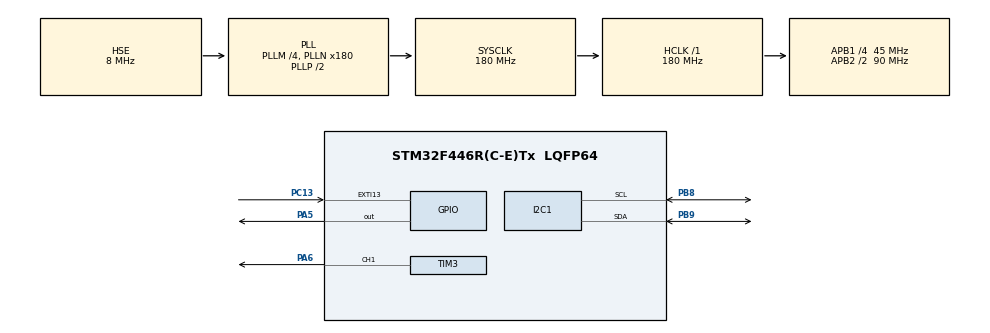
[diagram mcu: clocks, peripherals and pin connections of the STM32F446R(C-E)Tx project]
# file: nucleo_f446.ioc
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Mcu.Family=STM32F4
Mcu.Name=STM32F446R(C-E)Tx
Mcu.Package=LQFP64
NUCLEO-F446RE.BUTTON=1
NUCLEO-F446RE.LD1=true
NVIC.EXTI15_10_IRQn=true\:0\:0\:false\:false\:true\:false\:true\:true
NVIC.PriorityGroup=NVIC_PRIORITYGROUP_0
NVIC.TIM6_DAC_IRQn=true\:0\:0\:false\:false\:true\:false\:true\:true
NVIC.TimeBase=TIM6_DAC_IRQn
NVIC.TimeBaseIP=TIM6
PA13.GPIO_Label=TMS
PA13.Mode=Serial_Wire
PA13.Signal=SYS_JTMS-SWDIO
PA14.GPIO_Label=TCK
PA14.Mode=Serial_Wire
PA14.Signal=SYS_JTCK-SWCLK
PA2.GPIO_Label=USART_TX
PA2.Signal=USART2_TX
PA3.GPIO_Label=USART_RX
PA3.Signal=USART2_RX
PA5.Signal=GPIO_Output
PA6.Signal=S_TIM3_CH1
PB3.GPIO_Label=SWO
PB3.Signal=SYS_JTDO-SWO
PB8.Mode=I2C
PB8.Signal=I2C1_SCL
PB9.Mode=I2C
PB9.Signal=I2C1_SDA
PC13.Signal=GPXTI13
PC14-OSC32_IN.Signal=RCC_OSC32_IN
PC15-OSC32_OUT.Signal=RCC_OSC32_OUT
PH0-OSC_IN.Mode=HSE-External-Clock-Source
PH0-OSC_IN.Signal=RCC_OSC_IN
PH1-OSC_OUT.Mode=HSE-External-Clock-Source
PH1-OSC_OUT.Signal=RCC_OSC_OUT
ProjectManager.HeapSize=0x200
ProjectManager.StackSize=0x400
ProjectManager.TargetToolchain=CMake
RCC.AHBFreq_Value=180000000
RCC.APB1CLKDivider=RCC_HCLK_DIV4
RCC.APB1Freq_Value=45000000
RCC.APB1TimFreq_Value=90000000
RCC.APB2CLKDivider=RCC_HCLK_DIV2
RCC.APB2Freq_Value=90000000
RCC.APB2TimFreq_Value=180000000
RCC.CortexFreq_Value=180000000
RCC.FLatency-AdvancedSettings=FLASH_LATENCY_5
RCC.HCLKFreq_Value=180000000
RCC.HSE_VALUE=8000000
RCC.HSI_VALUE=16000000
RCC.LSE_VALUE=32768
RCC.PLLM=4
RCC.PLLN=180
RCC.PLLSourceVirtual=RCC_PLLSOURCE_HSE
RCC.SYSCLKFreq_VALUE=180000000
RCC.SYSCLKSource=RCC_SYSCLKSOURCE_PLLCLK
RCC.USBFreq_Value=180000000
RCC.VCOOutputFreq_Value=360000000
SH.S_TIM3_CH1.0=TIM3_CH1,PWM Generation1 CH1
TIM3.AutoReloadPreload=TIM_AUTORELOAD_PRELOAD_ENABLE
TIM3.Channel-PWM\ Generation1\ CH1=TIM_CHANNEL_1
TIM3.Period=19999
TIM3.Prescaler=89
TIM3.Pulse-PWM\ Generation1\ CH1=1500
VP_NUCLEO-F446RE_VS_BSP_COMMON.Mode=COMMON
VP_SYS_VS_tim6.Mode=TIM6
board=NUCLEO-F446RE

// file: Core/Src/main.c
/* USER CODE BEGIN Header */
/**
 ******************************************************************************
 * @file           : main.c
 * @brief          : Main program body
 ******************************************************************************
 * @attention
 *
 * Copyright (c) 2026 STMicroelectronics.
 * All rights reserved.
 *
 * This software is licensed under terms that can be found in the LICENSE file
 * in the root directory of this software component.
 * If no LICENSE file comes with this software, it is provided AS-IS.
 *
 ******************************************************************************
 */
/* USER CODE END Header */
#include "main.h"
#include "i2c.h"
#include "tim.h"
#include "gpio.h"

/* USER CODE BEGIN Includes */
#include "bno055_port.h"
#include "steering_port.h"

/* USER CODE END Includes */

void SystemClock_Config(void);

int main(void)
{

    /* MCU Configuration--------------------------------------------------------*/

    /* Reset of all peripherals, Initializes the Flash interface and the Systick. */
    HAL_Init();

    /* Configure the system clock */
    SystemClock_Config();

    /* Initialize all configured peripherals */
    MX_GPIO_Init();
    MX_I2C1_Init();
    MX_TIM3_Init();
    /* USER CODE BEGIN 2 */

    bno055_t bno055_dev = {0};
    bno055_port_init(&bno055_dev, &hi2c1);
    bno055_status_t imu_st = bno055_init(&bno055_dev, NULL);

    steering_dev_t steer_dev = {0};
    steering_cal_t steer_cal = {.left_us = 2000, .center_us = 1500, .right_us = 1000};
    steering_status_t steer_st = steering_port_init(&steer_dev, &htim3);

    if (steer_st == STEERING_OK) steer_st = steering_init(&steer_dev, &steer_cal);

    /* USER CODE END 2 */
    static uint16_t g_steer_us = 1500;

    /* Initialize leds */
    BSP_LED_Init(LED2);

    /* Initialize USER push-button, will be used to trigger an interrupt each time it's pressed.*/
    BSP_PB_Init(BUTTON_USER, BUTTON_MODE_EXTI);

    /* Infinite loop */
    while (1)
    {

        /* USER CODE BEGIN 3 */
        steering_set_pulse_us(&steer_dev, g_steer_us);
        bno055_vec3_t accel, gyro;
        bno055_read_accel(&bno055_dev, &accel);
        bno055_read_gyro(&bno055_dev, &gyro);
        HAL_Delay(100);
    }
    /* USER CODE END 3 */
}

void SystemClock_Config(void)
{
    RCC_OscInitTypeDef RCC_OscInitStruct = {0};
    RCC_ClkInitTypeDef RCC_ClkInitStruct = {0};

    /** Configure the main internal regulator output voltage
     */
    __HAL_RCC_PWR_CLK_ENABLE();
    __HAL_PWR_VOLTAGESCALING_CONFIG(PWR_REGULATOR_VOLTAGE_SCALE1);

    /** Initializes the RCC Oscillators according to the specified parameters
     * in the RCC_OscInitTypeDef structure.
     */
    RCC_OscInitStruct.OscillatorType = RCC_OSCILLATORTYPE_HSE;
    RCC_OscInitStruct.HSEState = RCC_HSE_BYPASS;
    RCC_OscInitStruct.PLL.PLLState = RCC_PLL_ON;
    RCC_OscInitStruct.PLL.PLLSource = RCC_PLLSOURCE_HSE;
    RCC_OscInitStruct.PLL.PLLM = 4;
    RCC_OscInitStruct.PLL.PLLN = 180;
    RCC_OscInitStruct.PLL.PLLP = RCC_PLLP_DIV2;
    RCC_OscInitStruct.PLL.PLLQ = 2;
    RCC_OscInitStruct.PLL.PLLR = 2;
    if (HAL_RCC_OscConfig(&RCC_OscInitStruct) != HAL_OK)
    {
        Error_Handler();
    }

    /** Activate the Over-Drive mode
     */
    if (HAL_PWREx_EnableOverDrive() != HAL_OK)
    {
        Error_Handler();
    }

    /** Initializes the CPU, AHB and APB buses clocks
     */
    RCC_ClkInitStruct.ClockType =
        RCC_CLOCKTYPE_HCLK | RCC_CLOCKTYPE_SYSCLK | RCC_CLOCKTYPE_PCLK1 | RCC_CLOCKTYPE_PCLK2;
    RCC_ClkInitStruct.SYSCLKSource = RCC_SYSCLKSOURCE_PLLCLK;
    RCC_ClkInitStruct.AHBCLKDivider = RCC_SYSCLK_DIV1;
    RCC_ClkInitStruct.APB1CLKDivider = RCC_HCLK_DIV4;
    RCC_ClkInitStruct.APB2CLKDivider = RCC_HCLK_DIV2;

    if (HAL_RCC_ClockConfig(&RCC_ClkInitStruct, FLASH_LATENCY_5) != HAL_OK)
    {
        Error_Handler();
    }
}

void HAL_TIM_PeriodElapsedCallback(TIM_HandleTypeDef *htim)
{
    if (htim->Instance == TIM6)
    {
        HAL_IncTick();
    }
}

void Error_Handler(void)
{
    __disable_irq();
    while (1)
    {
    }
}
